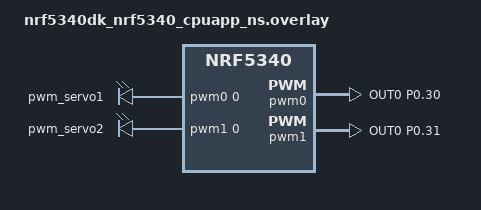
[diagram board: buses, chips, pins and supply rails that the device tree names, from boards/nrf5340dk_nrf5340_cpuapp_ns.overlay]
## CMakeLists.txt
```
cmake_minimum_required(VERSION 3.20.0)
find_package(Zephyr REQUIRED HINTS $ENV{ZEPHYR_BASE})

project(knull)

target_sources(app PRIVATE src/main.c)
```

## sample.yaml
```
sample:
  description: nRF Connect SDK Intermediate Course by Nordic Developer Academy (https://academy.nordicsemi.com/)
  name: nRF Connect SDK Intermediate Course (Lesson 4 - Exercise 2)
tests:
  sample.bluetooth.peripheral_lbs:
    build_only: true
    integration_platforms:
      - nrf52dk_nrf52832
      - nrf52840dk_nrf52840
      - nrf5340dk_nrf5340_cpuapp
      - nrf5340dk_nrf5340_cpuapp_ns
      - thingy53_nrf5340_cpuapp
      - thingy53_nrf5340_cpuapp_ns
    platform_allow: nrf52dk_nrf52832 nrf52840dk_nrf52840 nrf52dk_nrf52810
      nrf5340dk_nrf5340_cpuapp nrf5340dk_nrf5340_cpuapp_ns thingy53_nrf5340_cpuapp
      thingy53_nrf5340_cpuapp_ns
    tags: bluetooth ci_build
  sample.bluetooth.peripheral_lbs_minimal:
    build_only: true
    extra_args: OVERLAY_CONFIG=prj_minimal.conf
    integration_platforms:
      - nrf52dk_nrf52810
      - nrf52840dk_nrf52811
      - nrf52833dk_nrf52820
    platform_allow: nrf52dk_nrf52810 nrf52840dk_nrf52811 nrf52833dk_nrf52820
    tags: bluetooth ci_build
  sample.bluetooth.peripheral_lbs_no_security:
    build_only: true
    extra_args: CONFIG_BT_LBS_SECURITY_ENABLED=n
    integration_platforms:
      - nrf52dk_nrf52832
      - nrf52840dk_nrf52840
      - nrf5340dk_nrf5340_cpuapp
      - nrf5340dk_nrf5340_cpuapp_ns
      - thingy53_nrf5340_cpuapp
      - thingy53_nrf5340_cpuapp_ns
    platform_allow: nrf52dk_nrf52832 nrf52840dk_nrf52840 nrf52dk_nrf52810
      nrf5340dk_nrf5340_cpuapp nrf5340dk_nrf5340_cpuapp_ns thingy53_nrf5340_cpuapp
      thingy53_nrf5340_cpuapp_ns
    tags: bluetooth ci_build
```

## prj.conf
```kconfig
# Logger module
CONFIG_LOG=y

# Button and LED library
CONFIG_DK_LIBRARY=y

# Bluetooth LE
CONFIG_BT=y
CONFIG_BT_PERIPHERAL=y
CONFIG_BT_DEVICE_NAME="Nordic_PWM_Control"

# Enable LBS Service
CONFIG_BT_LBS=y
CONFIG_BT_LBS_POLL_BUTTON=y

# PWM settings
CONFIG_PWM=y
CONFIG_PWM_LOG_LEVEL_DBG=y

# Increase stack size for the main thread and system workqueue
CONFIG_SYSTEM_WORKQUEUE_STACK_SIZE=2048
CONFIG_MAIN_STACK_SIZE=2048

CONFIG_PINCTRL=y
```

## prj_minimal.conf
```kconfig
CONFIG_BT_SMP=y
CONFIG_BT_PERIPHERAL=y
CONFIG_BT_DIS=y
CONFIG_BT_DIS_PNP=n
CONFIG_BT_BAS=y
CONFIG_BT_HRS=y
CONFIG_BT_DEVICE_NAME="Zephyr Heartrate Sensor"
CONFIG_BT_DEVICE_APPEARANCE=833

# Drivers and peripherals
CONFIG_I2C=n
CONFIG_WATCHDOG=n
CONFIG_PINCTRL=n
CONFIG_SPI=n
CONFIG_GPIO=n
CONFIG_SERIAL=n

# Power management
CONFIG_PM=n

# Interrupts
CONFIG_DYNAMIC_INTERRUPTS=n
CONFIG_IRQ_OFFLOAD=n

# Memory protection
CONFIG_THREAD_STACK_INFO=n
CONFIG_THREAD_CUSTOM_DATA=n
CONFIG_FPU=n

# Boot
CONFIG_BOOT_BANNER=n
CONFIG_BOOT_DELAY=0

# Console
CONFIG_CONSOLE=n
CONFIG_UART_CONSOLE=n
CONFIG_STDOUT_CONSOLE=n
CONFIG_PRINTK=n
CONFIG_EARLY_CONSOLE=n

# Build
CONFIG_SIZE_OPTIMIZATIONS=y

# ARM
CONFIG_ARM_MPU=n

# In order to correctly tune the stack sizes for the threads the following
# Configurations can enabled to print the current use:
# CONFIG_THREAD_NAME=y
# CONFIG_THREAD_ANALYZER=y
# CONFIG_THREAD_ANALYZER_AUTO=y
# CONFIG_THREAD_ANALYZER_RUN_UNLOCKED=y
# CONFIG_THREAD_ANALYZER_USE_PRINTK=y
# CONFIG_THREAD_ANALYZER_AUTO_INTERVAL=20
# CONFIG_CONSOLE=y
# CONFIG_UART_CONSOLE=y
# CONFIG_SERIAL=y
# CONFIG_PRINTK=y

# Example output of thread analyzer
# BT RX               : STACK: unused 576 usage 448 / 1024 (43 %); CPU: 0 %
# BT RX pri           : STACK: unused 260 usage 188 / 448 (41 %); CPU: 0 %
# BT ECC              : STACK: unused 256 usage 888 / 1144 (77 %); CPU: 1 %
# BT TX               : STACK: unused 296 usage 344 / 640 (53 %); CPU: 0 %
# thread_analyzer     : STACK: unused 128 usage 384 / 512 (75 %); CPU: 1 %
# sysworkq            : STACK: unused 856 usage 168 / 1024 (16 %); CPU: 0 %
# logging             : STACK: unused 232 usage 536 / 768 (69 %); CPU: 0 %
# idle 00             : STACK: unused 208 usage 48 / 256 (18 %); CPU: 97 %
# main                : STACK: unused 576 usage 448 / 1024 (43 %); CPU: 0 %
CONFIG_BT_RX_STACK_SIZE=1024
CONFIG_BT_CTLR_RX_PRIO_STACK_SIZE=448
CONFIG_BT_HCI_TX_STACK_SIZE_WITH_PROMPT=y
CONFIG_BT_HCI_TX_STACK_SIZE=640
CONFIG_SYSTEM_WORKQUEUE_STACK_SIZE=512
CONFIG_IDLE_STACK_SIZE=128
CONFIG_MAIN_STACK_SIZE=640
CONFIG_ISR_STACK_SIZE=1024

# Disable features not needed
CONFIG_TIMESLICING=n
CONFIG_COMMON_LIBC_MALLOC=n
CONFIG_LOG=n
CONFIG_ASSERT=n

# Disable Bluetooth features not needed
# CONFIG_BT_DEBUG_NONE=y
CONFIG_BT_ASSERT=n
CONFIG_BT_DATA_LEN_UPDATE=n
CONFIG_BT_PHY_UPDATE=n
CONFIG_BT_GATT_CACHING=n
CONFIG_BT_GATT_SERVICE_CHANGED=n
CONFIG_BT_GAP_PERIPHERAL_PREF_PARAMS=n
CONFIG_BT_SETTINGS_CCC_LAZY_LOADING=y
CONFIG_BT_HCI_VS_EXT=n

# Disable Bluetooth controller features not needed
CONFIG_BT_CTLR_PRIVACY=n
CONFIG_BT_CTLR_PHY_2M=n

# Reduce Bluetooth buffers
CONFIG_BT_BUF_EVT_DISCARDABLE_COUNT=1
CONFIG_BT_BUF_EVT_DISCARDABLE_SIZE=45
CONFIG_BT_BUF_ACL_RX_COUNT=2
CONFIG_BT_BUF_EVT_RX_COUNT=2

CONFIG_BT_CONN_TX_MAX=2
CONFIG_BT_L2CAP_TX_BUF_COUNT=2
CONFIG_BT_CTLR_RX_BUFFERS=1
CONFIG_BT_BUF_ACL_TX_COUNT=3
CONFIG_BT_BUF_ACL_TX_SIZE=27
```

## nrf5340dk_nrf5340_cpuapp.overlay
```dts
/* Device Tree Overlay */

&pwm0 {
    status = "okay";
    label = "PWM_0";
    pinctrl-0 = <&pwm0_default>;
    pinctrl-names = "default";
};

&pwm0_default: pwm0_default {
    group1 {
        psels = <NRF_PSEL(PWM_OUT0, 0, 28)>; // Configure PWM output on P0.31
    };
};
```

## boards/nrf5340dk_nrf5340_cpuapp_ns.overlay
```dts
/* Device Tree Overlay for nRF5340 DK */

/ {
    aliases {
        pwm-servo1 = &pwm_servo1;
        pwm-servo2 = &pwm_servo2;
    };

    pwmleds {
        compatible = "pwm-leds";
        pwm_servo1: pwm_servo1 {
            pwms = <&pwm0 0 PWM_MSEC(20) PWM_POLARITY_NORMAL>;
        };
        pwm_servo2: pwm_servo2 {
            pwms = <&pwm1 0 PWM_MSEC(20) PWM_POLARITY_NORMAL>;
        };
    };
};

/* Enable PWM0 and assign pin P0.30 for Servo 1 */
&pwm0 {
    status = "okay";
    pinctrl-0 = <&pwm0_default>;
    pinctrl-1 = <&pwm0_sleep>;
    pinctrl-names = "default", "sleep";
};

/* Enable PWM1 and assign pin P0.31 for Servo 2 */
&pwm1 {
    status = "okay";
    pinctrl-0 = <&pwm1_default>;
    pinctrl-1 = <&pwm1_sleep>;
    pinctrl-names = "default", "sleep";
};

/* Define pin control configurations */
&pinctrl {
    /* PWM0 Pin Configuration */
    pwm0_default: pwm0_default {
        group1 {
            psels = <NRF_PSEL(PWM_OUT0, 0, 30)>; /* Pin 30 for PWM0 */
            nordic,invert;
        };
    };

    pwm0_sleep: pwm0_sleep {
        group1 {
            psels = <NRF_PSEL(PWM_OUT0, 0, 30)>;
            low-power-enable;
        };
    };

    /* PWM1 Pin Configuration */
    pwm1_default: pwm1_default {
        group1 {
            psels = <NRF_PSEL(PWM_OUT0, 0, 31)>; /* Pin 31 for PWM1 */
            nordic,invert;
        };
    };

    pwm1_sleep: pwm1_sleep {
        group1 {
            psels = <NRF_PSEL(PWM_OUT0, 0, 31)>;
            low-power-enable;
        };
    };
};
```

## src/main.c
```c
#include <zephyr/kernel.h>
#include <zephyr/device.h>
#include <zephyr/devicetree.h>
#include <zephyr/logging/log.h>
#include <zephyr/drivers/adc.h>
#include <zephyr/bluetooth/bluetooth.h>
#include <zephyr/bluetooth/hci.h>
#include <zephyr/bluetooth/gatt.h>
#include <zephyr/bluetooth/services/hrs.h>

/* Constants for heart rate calculation */
#define SAMPLE_RATE 1000  // 1000 Hz sampling rate (1ms per sample)
#define PEAK_THRESHOLD 2000  // Adjust this based on your sensor's signal
#define MIN_PEAK_DISTANCE 600  // Minimum time between peaks (600 ms, ~100 BPM max)

static const struct adc_dt_spec adc_channel = ADC_DT_SPEC_GET(DT_PATH(zephyr_user));

LOG_MODULE_REGISTER(HeartRateMonitor, LOG_LEVEL_DBG);

/* Bluetooth Advertising Data */
static const struct bt_data ad[] = {
    BT_DATA_BYTES(BT_DATA_FLAGS, (BT_LE_AD_GENERAL | BT_LE_AD_NO_BREDR)),
    BT_DATA_BYTES(BT_DATA_UUID16_ALL, BT_UUID_16_ENCODE(BT_UUID_HRS_VAL))
};

/* Callback for Bluetooth connection */
static void connected(struct bt_conn *conn, uint8_t err) {
    if (err) {
        LOG_ERR("Connection failed (err %u)", err);
    } else {
        LOG_INF("Connected");
    }
}

/* Callback for Bluetooth disconnection */
static void disconnected(struct bt_conn *conn, uint8_t reason) {
    LOG_INF("Disconnected (reason %u)", reason);
}

BT_CONN_CB_DEFINE(conn_callbacks) = {
    .connected = connected,
    .disconnected = disconnected,
};

/* Function to initialize BLE */
static void bt_ready(void) {
    int err;

    err = bt_le_adv_start(BT_LE_ADV_CONN_NAME, ad, ARRAY_SIZE(ad), NULL, 0);
    if (err) {
        LOG_ERR("Advertising failed to start (err %d)", err);
    } else {
        LOG_INF("Advertising successfully started");
    }
}

int main(void) {
    int err;
    int16_t adc_value;
    uint32_t last_peak_time = 0;  // Timestamp of the last detected peak
    uint32_t current_time;
    uint32_t bpm = 0;  // To store calculated BPM

    struct adc_sequence sequence = {
        .buffer = &adc_value,
        .buffer_size = sizeof(adc_value),
    };

    /* Initialize Bluetooth */
    err = bt_enable(NULL);
    if (err) {
        LOG_ERR("Bluetooth init failed (err %d)", err);
        return 0;
    }
    bt_ready();

    if (!adc_is_ready_dt(&adc_channel)) {
        LOG_ERR("ADC device not ready.");
        return 0;
    }

    err = adc_channel_setup_dt(&adc_channel);
    if (err < 0) {
        LOG_ERR("Could not set up ADC channel (%d)", err);
        return 0;
    }

    err = adc_sequence_init_dt(&adc_channel, &sequence);
    if (err < 0) {
        LOG_ERR("Could not initialize ADC sequence.");
        return 0;
    }

    /* Heart rate measurement loop */
    while (1) {
        err = adc_read(adc_channel.dev, &sequence);
        if (err < 0) {
            LOG_ERR("ADC read error (%d)", err);
            continue;
        }

        current_time = k_uptime_get_32();  // Get current time in ms

        // Check if the ADC value exceeds the threshold, indicating a peak
        if (adc_value > PEAK_THRESHOLD) {
            if (current_time - last_peak_time > MIN_PEAK_DISTANCE) {
                // A peak is detected, calculate BPM
                uint32_t time_diff = current_time - last_peak_time;  // Time between two peaks
                bpm = (60000 / time_diff);  // Calculate BPM

                // Check if the BPM is 99, which indicates no valid heartbeat detected
                if (bpm == 99) {
                    LOG_INF("No heartbeat detected.");
                } else {
                    LOG_INF("Heartbeat detected! BPM: %d", bpm);

                    // Notify the BLE heart rate service with the new BPM value
                    bt_hrs_notify(bpm);
                }

                last_peak_time = current_time;  // Update last peak time
            }
        }

        k_sleep(K_MSEC(1000 / SAMPLE_RATE));  // Sleep to achieve the desired sampling rate
    }

    return 0;
}
```
